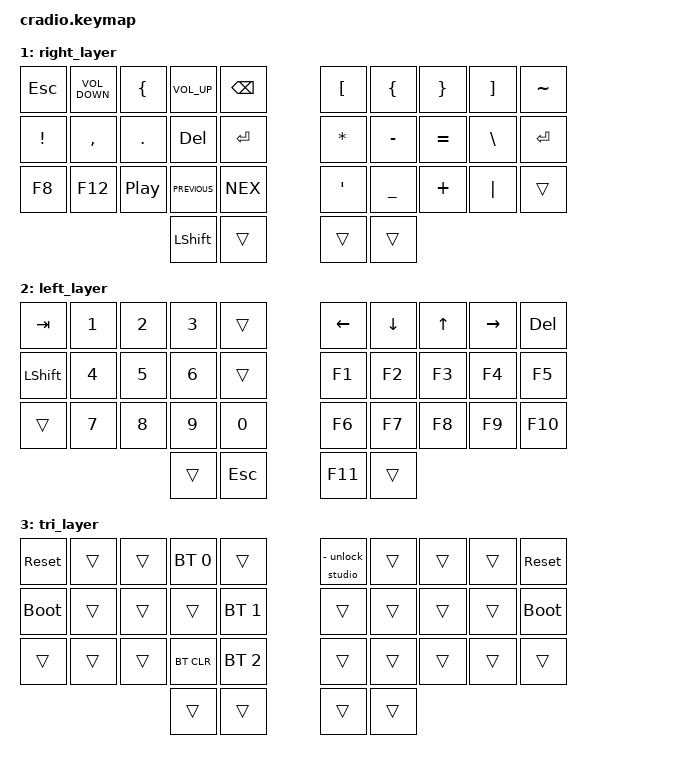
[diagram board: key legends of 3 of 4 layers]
// Copyright (c) 2022 The ZMK Contributors
// SPDX-License-Identifier: MIT

#include <behaviors.dtsi>
#include <dt-bindings/zmk/keys.h>
#include <dt-bindings/zmk/bt.h>

// Home row mods macro
#define HRML(k1,k2,k3,k4) &ht LSHFT k1  &ht LALT k2  &ht LCTRL k3  &ht LGUI k4
#define HRMR(k1,k2,k3,k4) &ht RGUI k1  &ht RCTRL k2  &ht RALT k3  &ht RSHFT k4

/ {
    behaviors {
        ht: hold_tap {
            compatible = "zmk,behavior-hold-tap";
            #binding-cells = <2>;
            flavor = "tap-preferred";
            tapping-term-ms = <220>;
            quick-tap-ms = <150>;
            require-prior-idle-ms = <100>;
            bindings = <&kp>, <&kp>;
        };
    };

    conditional_layers {
        compatible = "zmk,conditional-layers";
        tri_layer {
            if-layers = <1 2>;
            then-layer = <3>;
        };
    };

    keymap {
        compatible = "zmk,keymap";
        default_layer {
            bindings = <
        //╭──────────┬──────────┬──────────┬──────────┬──────────╮   ╭──────────┬──────────┬──────────┬──────────┬──────────╮
        //│  Q       │  W       │  E       │  R       │  T       │   │  Y       │  U       │  I       │  O       │  P       │
            &kp Q      &kp W      &kp E      &kp R      &kp T          &kp Y      &kp U      &kp I      &kp O      &kp P
        //├──────────┼──────────┼──────────┼──────────┼──────────┤   ├──────────┼──────────┼──────────┼──────────┼──────────┤
        //│  A       │  S       │  D       │  F       │  G       │   │  H       │  J       │  K       │  L       │ : ;      │
            HRML(A,        S,         D,         F)     &kp G          &kp H      HRMR(J,        K,         L,        SEMI)
        //├──────────┼──────────┼──────────┼──────────┼──────────┤   ├──────────┼──────────┼──────────┼──────────┼──────────┤
        //│  Z       │  X       │  C       │  V       │  B       │   │  N       │  M       │ , <      │ . >      │ / ?      │
            &kp Z      &kp X      &kp C      &kp V      &kp B          &kp N      &kp M      &kp COMMA  &kp DOT    &kp FSLH
        //╰──────────┴──────────┴──────────┼──────────┼──────────┤   ├──────────┼──────────┼──────────┴──────────┴──────────╯
                                            &lt 2 Z    &lt 1 SPACE   &lt 1 SPACE  &lt 2 BSPC
        //                                 ╰──────────┴──────────╯   ╰──────────┴──────────╯
            >;
        };

        right_layer {f
            bindings = <
        //╭──────────┬──────────┬──────────┬──────────┬──────────╮   ╭──────────┬──────────┬──────────┬──────────┬──────────╮
        //│   ESC    │  V up    │  Spot    │  V down  │ Backspace|   │  [       │  {       │  }       │  ]       │  ~       │
            &kp ESC &kp C_VOLUME_DOWN &kp LBRC &kp C_VOLUME_UP &kp BSPC &kp LBKT  &kp LBRC   &kp RBRC   &kp RBKT   &kp TILDE
        //├──────────┼──────────┼──────────┼──────────┼──────────┤   ├──────────┼──────────┼──────────┼──────────┼──────────┤
        //│  !       │  , <     │ . >      │ DELETE   │  ENTER   │   │  *       │  -       │  =       │  \       │ ENTER    │
            &kp EXCL   &kp COMMA  &kp DOT   &kp DEL   &kp ENTER      &kp ASTRK  &kp MINUS  &kp EQUAL  &kp BSLH   &kp ENTER
        //├──────────┼──────────┼──────────┼──────────┼──────────┤   ├──────────┼──────────┼──────────┼──────────┼──────────┤
        //│          │          │          │          │          │   │  ' "     │  _       │  +       │  │       │          │
            &kp F8     &kp F12     &kp C_PLAY_PAUSE     &kp C_PREVIOUS   &kp C_NEX    &kp SQT   &kp UNDER  &kp PLUS   &kp PIPE   &trans
        //╰──────────┴──────────┴──────────┼──────────┼──────────┤   ├──────────┼──────────┼──────────┴──────────┴──────────╯
                                             &kp LSHIFT  &trans         &trans     &trans
        //                                 ╰──────────┴──────────╯   ╰──────────┴──────────╯
            >;
        };

        left_layer {
            bindings = <
        //╭──────────┬──────────┬──────────┬──────────┬──────────╮   ╭──────────┬──────────┬──────────┬──────────┬──────────╮
        //│ TAB      │ 1        │ 2        │ 3        │          │   │ LEFT     │ DOWN     │ UP       │ RIGHT    │  DELETE  │
            &kp TAB   &kp N1      &kp N2     &kp N3     &trans         &kp LEFT   &kp DOWN   &kp UP   &kp RIGHT    &kp DELETE
        //├──────────┼──────────┼──────────┼──────────┼──────────┤   ├──────────┼──────────┼──────────┼──────────┼──────────┤
        //│ Shift    │ 4        │ 5        │ 6        │          │   │ F1       │ F2       │ F3       │ F4       │  F5      │
            &kp LSHIFT &kp N4     &kp N5     &kp N6      &trans         &kp F1    &kp F2      &kp F3    &kp F4     &kp F5
        //├──────────┼──────────┼──────────┼──────────┼──────────┤   ├──────────┼──────────┼──────────┼──────────┼──────────┤
        //│          │ 7        │  8       │  9       │  0       │   │ F6       │  F7      │  F8      │  F9      │ F10      │
            &trans      &kp N7     &kp N8     &kp N9     &kp N0         &kp F6     &kp F7     &kp F8     &kp F9     &kp F10
        //╰──────────┴──────────┴──────────┼──────────┼──────────┤   ├──────────┼──────────┼──────────┴──────────┴──────────╯
                                             &trans    &kp ESC        &kp F11     &trans
        //                                 ╰──────────┴──────────╯   ╰──────────┴──────────╯
            >;
        };

        tri_layer {
            bindings = <
        //╭──────────┬──────────┬──────────┬──────────┬──────────╮   ╭──────────┬──────────┬──────────┬──────────┬──────────╮
        //│ RESET    │          │          │ PROFILE 0│          │   │          │          │          │          │  RESET   │
           &sys_reset  &trans     &trans     &bt BT_SEL 0  &trans      &studio-unlock     &trans     &trans     &trans    &sys_reset
        //├──────────┼──────────┼──────────┼──────────┼──────────┤   ├──────────┼──────────┼──────────┼──────────┼──────────┤
        //│BOOTLOADER│          │          │          │PROFILE 1 │   │          │          │          │          │BOOTLOADER│
          &bootloader  &trans     &trans     &trans    &bt BT_SEL 1    &trans     &trans     &trans     &trans    &bootloader
        //├──────────┼──────────┼──────────┼──────────┼──────────┤   ├──────────┼──────────┼──────────┼──────────┼──────────┤
        //│          │          │          │ CLEAR BT │PROFILE 2 │   │          │          │          │          │          │
            &trans     &trans     &trans    &bt BT_CLR &bt BT_SEL 2    &trans     &trans     &trans     &trans     &trans
        //╰──────────┴──────────┴──────────┼──────────┼──────────┤   ├──────────┼──────────┼──────────┴──────────┴──────────╯
                                             &trans     &trans         &trans     &trans
        //                                 ╰──────────┴──────────╯   ╰──────────┴──────────╯
            >;
        };
    };
};
